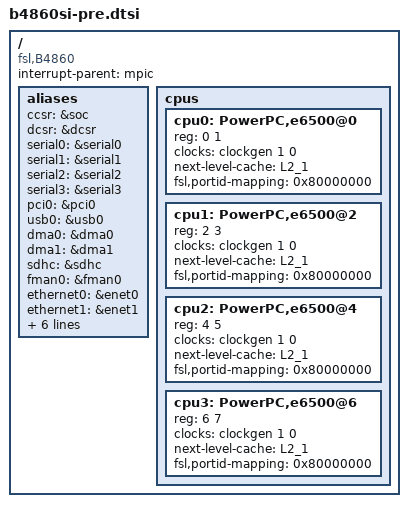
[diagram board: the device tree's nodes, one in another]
/dts-v1/;
/include/ "e6500_power_isa.dtsi"
/ {
	compatible = "fsl,B4860";
	#address-cells = <2>;
	#size-cells = <2>;
	interrupt-parent = <&mpic>;
	aliases {
		ccsr = &soc;
		dcsr = &dcsr;
		serial0 = &serial0;
		serial1 = &serial1;
		serial2 = &serial2;
		serial3 = &serial3;
		pci0 = &pci0;
		usb0 = &usb0;
		dma0 = &dma0;
		dma1 = &dma1;
		sdhc = &sdhc;
		fman0 = &fman0;
		ethernet0 = &enet0;
		ethernet1 = &enet1;
		ethernet2 = &enet2;
		ethernet3 = &enet3;
		ethernet4 = &enet4;
		ethernet5 = &enet5;
		ethernet6 = &enet6;
		ethernet7 = &enet7;
	};
	cpus {
		#address-cells = <1>;
		#size-cells = <0>;
		cpu0: PowerPC,e6500@0 {
			device_type = "cpu";
			reg = <0 1>;
			clocks = <&clockgen 1 0>;
			next-level-cache = <&L2_1>;
			fsl,portid-mapping = <0x80000000>;
		};
		cpu1: PowerPC,e6500@2 {
			device_type = "cpu";
			reg = <2 3>;
			clocks = <&clockgen 1 0>;
			next-level-cache = <&L2_1>;
			fsl,portid-mapping = <0x80000000>;
		};
		cpu2: PowerPC,e6500@4 {
			device_type = "cpu";
			reg = <4 5>;
			clocks = <&clockgen 1 0>;
			next-level-cache = <&L2_1>;
			fsl,portid-mapping = <0x80000000>;
		};
		cpu3: PowerPC,e6500@6 {
			device_type = "cpu";
			reg = <6 7>;
			clocks = <&clockgen 1 0>;
			next-level-cache = <&L2_1>;
			fsl,portid-mapping = <0x80000000>;
		};
	};
};
